# DMASS_BCDMA_0_BCDMA_BCCFG_48420000h register map
Vendor: Texas Instruments
Peripheral module from a debugger description file (folder AM275x).
Registers are 32-bit, read-write, reset 0x0 unless marked. A register's access mark holds for its fields unless they carry their own. Offsets are as the file gives them; lines under a group give offsets from that group; [hi:lo] are bit positions; {n}, {i} and the like mark numbered series; 'fields as' and 'values as' point back to an identical list; <NAME> marks a mode.

## bcdma_bccfg
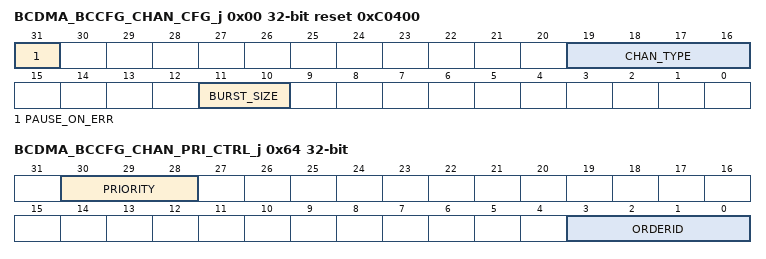
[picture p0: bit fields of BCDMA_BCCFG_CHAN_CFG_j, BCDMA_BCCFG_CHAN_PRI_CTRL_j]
0x00 BCDMA_BCCFG_CHAN_CFG_j access not given reset 0xC0400 — The Channel Configuration Register is used to initialize static mode settings for the Block Copy DMA channel. This register may only be written when the channel is disabled (tx_enable in realtime control reg is 0).
  [31] PAUSE_ON_ERR rw — Pause On Error: this field controls what the channel will do if an error or exception occurs during a data transfer. This field is encoded as follows: 0 = Channel will drop current work and move on 1 = Channel will pause and wait for SW to investigate and un-pause the channel. Reset Source: rst_mod_g_rst_n
  [19:16] CHAN_TYPE — Channel Type: this field controls and / or indicates the functional channel type for this channel and the work passing mechanism that the channel uses for communicating with the Host. Available channel types are as follows: 0-11 = RESERVED 12 = Channel performs Third Party Block Copy DMA transfers from memory to memory using pass by reference rings. 13-15 = RESERVED 12 Pass by reference block copy (access R/NA)
  [11:10] BURST_SIZE rw — Specifies the nominal burst size and alignment for data transfers on this channel. 0 = 32 Bytes 1 = 64 Bytes All other values are reserved The optimal burst size setting is 64 Bytes to maximize utilization of the channel FIFOs. Reset Source: rst_mod_g_rst_n
0x64 BCDMA_BCCFG_CHAN_PRI_CTRL_j — The priority control register is used to control the priority of the transactions which the DMA generates on it's initiator interface.
  [30:28] PRIORITY — Priority: This field contains the 3-bit value which will be output on the mem*_cpriority and mem_cepriority outputs during all transactions for this channel. Reset Source: rst_mod_g_rst_n
  [3:0] ORDERID — Order ID: This field contains the 4-bit value which will be output on the mem*_corderid output during all transactions for this channel. Reset Source: rst_mod_g_rst_n
0x80 BCDMA_BCCFG_CHAN_TST_SCHED_j — The Channel N Static Scheduler Configuration Register contains static configuration information which affects the conditions under which each channel will be given an opportunity to use the Tx DMA unit(s). The fields in this register are as follows:
  [1:0] PRIORITY — Scheduling Priority: These bits select which scheduling bin the channel will be placed in for bandwidth allocation of the Tx/Rx DMA units. This field is encoded as follows: 0 = High priority 1 = Medium - high priority 2 = Medium - low priority 3 = Low priority Arbitration between bins is performed in a strict priority fashion. High priority channels will always be serviced first. If no high priority channels are requesting then all medium-high priority channels will be serviced next. If no high priority or medium-high priority channels are requesting then all medium-low priority channels will be serviced next. When no other channels are requesting, the low priority channels will be serviced. All channels within a given bin are serviced in a round robin order. Only channels which are enabled and which have sufficient free space in their Per Channel FIFO will be included in the round robin arbitration. Reset Source: rst_mod_g_rst_n
